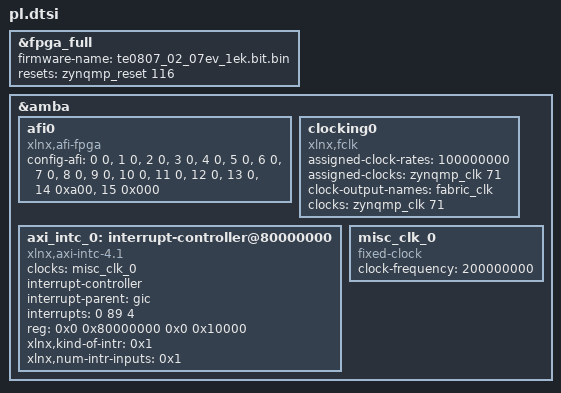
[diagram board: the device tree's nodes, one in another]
/*
 * CAUTION: This file is automatically generated by Xilinx.
 * Version: XSCT 2020.2
 * Today is: Tue Feb  1 14:50:57 2022
 */


/dts-v1/;
/plugin/;
/ {
	fragment@0 {
		target = <&fpga_full>;
		overlay0: __overlay__ {
			#address-cells = <2>;
			#size-cells = <2>;
			firmware-name = "te0807_02_07ev_1ek.bit.bin";
			resets = <&zynqmp_reset 116>;
		};
	};
	fragment@1 {
		target = <&amba>;
		overlay1: __overlay__ {
			afi0: afi0 {
				compatible = "xlnx,afi-fpga";
				config-afi = < 0 0>, <1 0>, <2 0>, <3 0>, <4 0>, <5 0>, <6 0>, <7 0>, <8 0>, <9 0>, <10 0>, <11 0>, <12 0>, <13 0>, <14 0xa00>, <15 0x000>;
			};
			clocking0: clocking0 {
				#clock-cells = <0>;
				assigned-clock-rates = <100000000>;
				assigned-clocks = <&zynqmp_clk 71>;
				clock-output-names = "fabric_clk";
				clocks = <&zynqmp_clk 71>;
				compatible = "xlnx,fclk";
			};
		};
	};
	fragment@2 {
		target = <&amba>;
		overlay2: __overlay__ {
			#address-cells = <2>;
			#size-cells = <2>;
			axi_intc_0: interrupt-controller@80000000 {
				#interrupt-cells = <2>;
				clock-names = "s_axi_aclk";
				clocks = <&misc_clk_0>;
				compatible = "xlnx,axi-intc-4.1", "xlnx,xps-intc-1.00.a";
				interrupt-controller ;
				interrupt-names = "irq";
				interrupt-parent = <&gic>;
				interrupts = <0 89 4>;
				reg = <0x0 0x80000000 0x0 0x10000>;
				xlnx,kind-of-intr = <0x1>;
				xlnx,num-intr-inputs = <0x1>;
			};
			misc_clk_0: misc_clk_0 {
				#clock-cells = <0>;
				clock-frequency = <200000000>;
				compatible = "fixed-clock";
			};
		};
	};
};
